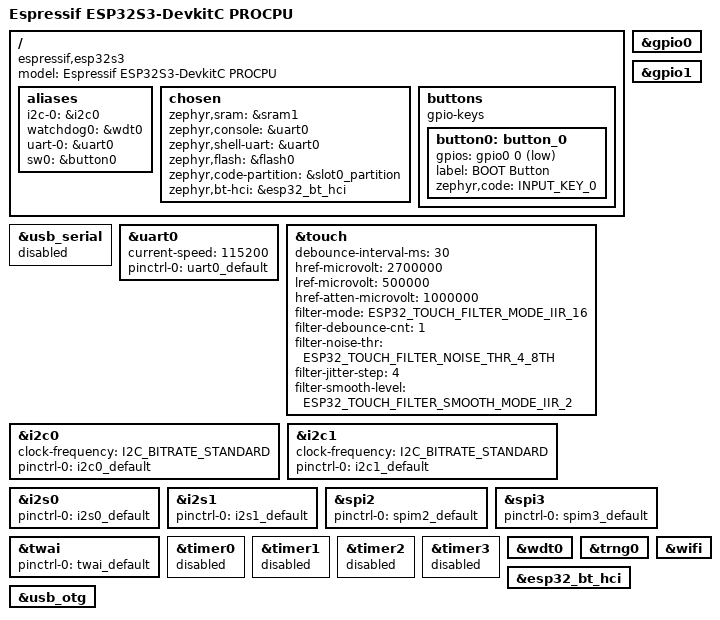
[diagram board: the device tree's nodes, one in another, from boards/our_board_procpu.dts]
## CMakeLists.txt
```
cmake_minimum_required(VERSION 3.20.0)

find_package(Zephyr REQUIRED)
project(my_zephyr_app)

target_sources(app PRIVATE src/main.cpp)
add_subdirectory(drivers/our_driver)
```

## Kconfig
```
source "Kconfig.zephyr"
rsource "drivers/our_driver/Kconfig"
```

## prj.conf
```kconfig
CONFIG_GPIO=y
CONFIG_LOG=y
CONFIG_APP_HEARTBEAT_PERIOD_MS=500
CONFIG_SPI=y
CONFIG_LED_STRIP=y
CONFIG_WS2812_STRIP_SPI=y
```

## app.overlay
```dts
/ {
    our_driver0: our_driver {
        compatible = "our,driver";
        gpios = <&gpio0 15 GPIO_ACTIVE_HIGH>;
        status = "okay";
    };
};
```

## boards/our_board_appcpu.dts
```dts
/*
 * Copyright (c) 2024 Espressif Systems (Shanghai) Co., Ltd.
 *
 * SPDX-License-Identifier: Apache-2.0
 */
/dts-v1/;

#include <espressif/esp32s3/esp32s3_wroom_n8.dtsi>
#include <espressif/partitions_0x0_amp.dtsi>
#include "our_board-pinctrl.dtsi"

/ {
	model = "Espressif ESP32S3-DevkitC APPCPU";
	compatible = "espressif,esp32s3";

	chosen {
		zephyr,sram = &sram1;
		zephyr,ipc_shm = &shm0;
		zephyr,ipc = &ipm0;
		zephyr,flash = &flash0;
		zephyr,code-partition = &slot0_appcpu_partition;
	};
};

&trng0 {
	status = "okay";
};

&ipm0 {
	status = "okay";
};
```

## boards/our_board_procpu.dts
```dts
/*
 * Copyright (c) 2024-2025 Espressif Systems (Shanghai) Co., Ltd.
 *
 * SPDX-License-Identifier: Apache-2.0
 */
/dts-v1/;

#include <espressif/esp32s3/esp32s3_wroom_n8.dtsi>
#include <zephyr/dt-bindings/input/input-event-codes.h>
#include <zephyr/dt-bindings/input/esp32-touch-sensor-input.h>
#include <espressif/partitions_0x0_amp.dtsi>
#include "our_board-pinctrl.dtsi"

/ {
	model = "Espressif ESP32S3-DevkitC PROCPU";
	compatible = "espressif,esp32s3";

	aliases {
		i2c-0 = &i2c0;
		watchdog0 = &wdt0;
		uart-0 = &uart0;
		sw0 = &button0;
	};

	chosen {
		zephyr,sram = &sram1;
		zephyr,console = &uart0;
		zephyr,shell-uart = &uart0;
		zephyr,flash = &flash0;
		zephyr,code-partition = &slot0_partition;
		zephyr,bt-hci = &esp32_bt_hci;
	};

	buttons {
		compatible = "gpio-keys";

		button0: button_0 {
			gpios = <&gpio0 0 (GPIO_PULL_UP | GPIO_ACTIVE_LOW)>;
			label = "BOOT Button";
			zephyr,code = <INPUT_KEY_0>;
		};
	};
};

&usb_serial {
	status = "disabled";
};

&uart0 {
	status = "okay";
	current-speed = <115200>;
	pinctrl-0 = <&uart0_default>;
	pinctrl-names = "default";
};

&gpio0 {
	status = "okay";
};

&gpio1 {
	status = "okay";
};

&touch {
	debounce-interval-ms = <30>;
	href-microvolt = <2700000>;
	lref-microvolt = <500000>;
	href-atten-microvolt = <1000000>;
	filter-mode = <ESP32_TOUCH_FILTER_MODE_IIR_16>;
	filter-debounce-cnt = <1>;
	filter-noise-thr = <ESP32_TOUCH_FILTER_NOISE_THR_4_8TH>;
	filter-jitter-step = <4>;
	filter-smooth-level = <ESP32_TOUCH_FILTER_SMOOTH_MODE_IIR_2>;
};

&i2c0 {
	clock-frequency = <I2C_BITRATE_STANDARD>;
	pinctrl-0 = <&i2c0_default>;
	pinctrl-names = "default";
};

&i2c1 {
	clock-frequency = <I2C_BITRATE_STANDARD>;
	pinctrl-0 = <&i2c1_default>;
	pinctrl-names = "default";
};

&i2s0 {
	pinctrl-0 = <&i2s0_default>;
	pinctrl-names = "default";
};

&i2s1 {
	pinctrl-0 = <&i2s1_default>;
	pinctrl-names = "default";
};

&spi2 {
	#address-cells = <1>;
	#size-cells = <0>;
	status = "okay";
	pinctrl-0 = <&spim2_default>;
	pinctrl-names = "default";
};

&spi3 {
	#address-cells = <1>;
	#size-cells = <0>;
	status = "okay";
	pinctrl-0 = <&spim3_default>;
	pinctrl-names = "default";
};

&twai {
	pinctrl-0 = <&twai_default>;
	pinctrl-names = "default";
};

&timer0 {
	status = "disabled";
};

&timer1 {
	status = "disabled";
};

&timer2 {
	status = "disabled";
};

&timer3 {
	status = "disabled";
};

&wdt0 {
	status = "okay";
};

&trng0 {
	status = "okay";
};

&esp32_bt_hci {
	status = "okay";
};

&wifi {
	status = "okay";
};

zephyr_udc0: &usb_otg {
	status = "okay";
};
```

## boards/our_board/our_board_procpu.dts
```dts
/dts-v1/;
#include <espressif/esp32s3/esp32s3_wroom_n8.dtsi>
#include <zephyr/dt-bindings/input/input-event-codes.h>
#include <zephyr/dt-bindings/input/esp32-touch-sensor-input.h>
#include <espressif/partitions_0x0_amp.dtsi>
#include "our_board-pinctrl.dtsi"

/ {
	model = "Our Board";
	compatible = "iomico,our-board,espressif,esp32s3";

	aliases {
		i2c-0 = &i2c0;
		watchdog0 = &wdt0;
		uart-0 = &uart0;
	};

	chosen {
		zephyr,sram = &sram1;
		zephyr,console = &uart0;
		zephyr,shell-uart = &uart0;
		zephyr,flash = &flash0;
		zephyr,code-partition = &slot0_partition;
		zephyr,bt-hci = &esp32_bt_hci;
	};
};

&uart0 {
	status = "okay";
	current-speed = <115200>;
	pinctrl-0 = <&uart0_default>;
	pinctrl-names = "default";
};
```

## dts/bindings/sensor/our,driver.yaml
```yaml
description: Our simple LED sensor driver.
compatible: "our,driver"
include: [base.yaml]
properties:
  gpios:
    type: phandle-array
    required: true
    description: GPIO pin connected to the on-board LED.
```

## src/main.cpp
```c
#include <zephyr/drivers/sensor.h>
#include <zephyr/kernel.h>
#include <zephyr/logging/log.h>

#include "our_driver.h"

LOG_MODULE_REGISTER(main, LOG_LEVEL_INF);

static const struct device *led_dev = DEVICE_DT_GET(DT_NODELABEL(our_driver0));

int main(void)
{
    if (!device_is_ready(led_dev)) {
        LOG_ERR("our_driver not ready");
        return -ENODEV;
    }

    /* Extension API: change blink_interval_ms in the driver's dynamic data */
    our_driver_set_blink_interval(led_dev, 500);

    struct sensor_value val;

    while (1) {
        /* sample_fetch turns the LED on */
        sensor_sample_fetch(led_dev);
        k_msleep(500);

        /* channel_get turns the LED off */
        sensor_channel_get(led_dev, SENSOR_CHAN_ALL, &val);
        k_msleep(500);
    }

    return 0;
}
```
